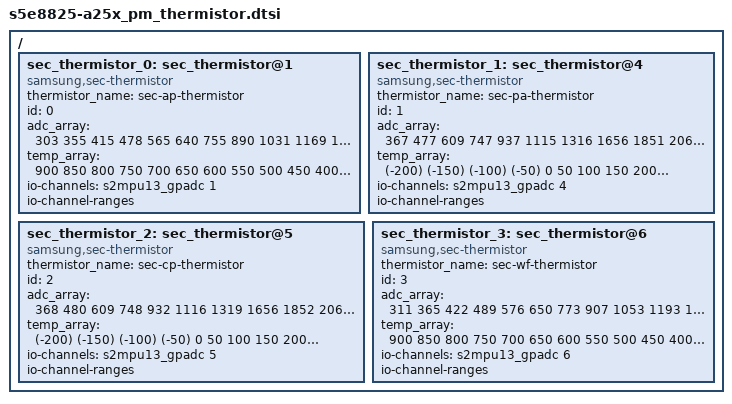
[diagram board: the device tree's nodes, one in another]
/*
 * SAMSUNG S5E8825 Power Management device tree source
 *
 * Copyright (c) 2026 Samsung Electronics Co., Ltd.
 *		http://www.samsung.com
 *
 * This program is free software; you can redistribute it and/or modify
 * it under the terms of the GNU General Public License version 2 as
 * published by the Free Software Foundation.
 */

/ {
	fragment@model {
		target-path = "/";
		__overlay__ {
			sec_thermistor_0: sec_thermistor@1 {
				compatible = "samsung,sec-thermistor";
				status = "okay";
				thermistor_name = "sec-ap-thermistor";
				id = <0>;

				adc_array = < 303 355 415 478 565 640 755 890 1031 1169
					1340 1552 1753 2007 2220 2416 2744 2943 3149 3320
					3473 3602 3691>;
				temp_array = <900 850 800 750 700 650 600 550 500 450
						400 350 300 250 200 150 100 50 0 (-50)
						(-100) (-150) (-200)>;

				io-channels = <&s2mpu13_gpadc 1>;
				io-channel-names = "adc-ap-temp";
				io-channel-ranges;
			};

			sec_thermistor_1: sec_thermistor@4 {
				compatible = "samsung,sec-thermistor";
				status = "okay";
				thermistor_name = "sec-pa-thermistor";
				id = <1>;

				adc_array = <367 477 609 747 937 1115 1316 1656 1851 2066
					2323 2528 2722 2893 3049 3196 3330 3452 3520 3600
					3673 3734 3787>;
				temp_array = <(-200) (-150) (-100) (-50) 0 50 100 150 200 250
					300 350 400 450 500 550 600 650 700 750
					800 850 900>;

				io-channels = <&s2mpu13_gpadc 4>;
				io-channel-names = "adc-pa-temp";
				io-channel-ranges;
			};

			sec_thermistor_2: sec_thermistor@5 {
				compatible = "samsung,sec-thermistor";
				status = "okay";
				thermistor_name = "sec-cp-thermistor";
				id = <2>;

				adc_array = <368 480 609 748 932 1116 1319 1656 1852 2068
					2325 2529 2724 2895 3049 3197 3330 3453 3521 3602
					3674 3734 3788>;
				temp_array = <(-200) (-150) (-100) (-50) 0 50 100 150 200 250
					300 350 400 450 500 550 600 650 700 750
					800 850 900>;

				io-channels = <&s2mpu13_gpadc 5>;
				io-channel-names = "adc-cp-temp";
				io-channel-ranges;
			};

			sec_thermistor_3: sec_thermistor@6 {
				compatible = "samsung,sec-thermistor";
				status = "okay";
				thermistor_name = "sec-wf-thermistor";
				id = <3>;

				adc_array = <311 365 422 489 576 650 773 907 1053 1193
					1364 1576 1776 2033 2249 2453 2764 2967 3166 3339
					3488 3616 3714>;
				temp_array = <900 850 800 750 700 650 600 550 500 450
						400 350 300 250 200 150 100 50 0 (-50)
						(-100) (-150) (-200)>;

				io-channels = <&s2mpu13_gpadc 6>;
				io-channel-names = "adc-wf-temp";
				io-channel-ranges;
			};
		}; /* end of __overlay__ */
	}; /* end of fragment */
}; /* end of root */
